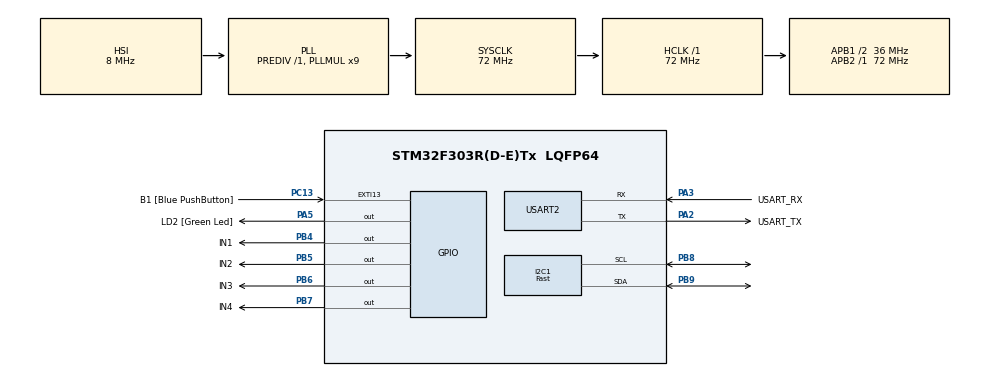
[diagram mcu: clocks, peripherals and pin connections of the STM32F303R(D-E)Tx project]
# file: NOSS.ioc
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I2C1.I2C_Speed_Mode=I2C_Fast
I2C1.Timing=0x0000020B
Mcu.Family=STM32F3
Mcu.Name=STM32F303R(D-E)Tx
Mcu.Package=LQFP64
NVIC.PriorityGroup=NVIC_PRIORITYGROUP_0
PA13.GPIO_Label=TMS
PA13.Mode=Serial_Wire
PA13.Signal=SYS_JTMS-SWDIO
PA14.GPIO_Label=TCK
PA14.Mode=Serial_Wire
PA14.Signal=SYS_JTCK-SWCLK
PA2.GPIO_Label=USART_TX
PA2.GPIO_Mode=GPIO_MODE_AF_PP
PA2.GPIO_PuPd=GPIO_NOPULL
PA2.GPIO_Speed=GPIO_SPEED_FREQ_LOW
PA2.Mode=Asynchronous
PA2.Signal=USART2_TX
PA3.GPIO_Label=USART_RX
PA3.GPIO_Mode=GPIO_MODE_AF_PP
PA3.GPIO_PuPd=GPIO_NOPULL
PA3.GPIO_Speed=GPIO_SPEED_FREQ_LOW
PA3.Mode=Asynchronous
PA3.Signal=USART2_RX
PA5.GPIO_Label=LD2 [Green Led]
PA5.GPIO_Mode=GPIO_MODE_OUTPUT_PP
PA5.GPIO_PuPd=GPIO_NOPULL
PA5.GPIO_Speed=GPIO_SPEED_FREQ_LOW
PA5.Signal=GPIO_Output
PB3.GPIO_Label=SWO
PB3.Signal=SYS_JTDO-TRACESWO
PB4.GPIO_Label=IN1
PB4.Signal=GPIO_Output
PB5.GPIO_Label=IN2
PB5.Signal=GPIO_Output
PB6.GPIO_Label=IN3
PB6.Signal=GPIO_Output
PB7.GPIO_Label=IN4
PB7.Signal=GPIO_Output
PB8.Mode=I2C
PB8.Signal=I2C1_SCL
PB9.Mode=I2C
PB9.Signal=I2C1_SDA
PC13.GPIO_Label=B1 [Blue PushButton]
PC13.GPIO_ModeDefaultEXTI=GPIO_MODE_IT_FALLING
PC13.Signal=GPXTI13
PC14-OSC32_IN.Mode=LSE-External-Oscillator
PC14-OSC32_IN.Signal=RCC_OSC32_IN
PC15-OSC32_OUT.Mode=LSE-External-Oscillator
PC15-OSC32_OUT.Signal=RCC_OSC32_OUT
PF0-OSC_IN.Mode=HSE-External-Clock-Source
PF0-OSC_IN.Signal=RCC_OSC_IN
PF1-OSC_OUT.Signal=RCC_OSC_OUT
ProjectManager.HeapSize=0x200
ProjectManager.StackSize=0x400
ProjectManager.TargetToolchain=SW4STM32
RCC.AHBFreq_Value=72000000
RCC.APB1CLKDivider=RCC_HCLK_DIV2
RCC.APB1Freq_Value=36000000
RCC.APB1TimFreq_Value=72000000
RCC.APB2Freq_Value=72000000
RCC.APB2TimFreq_Value=72000000
RCC.CortexFreq_Value=72000000
RCC.HCLKFreq_Value=72000000
RCC.HSE_VALUE=8000000
RCC.HSI_VALUE=8000000
RCC.PLLM=8
RCC.PLLMUL=RCC_PLL_MUL9
RCC.PLLN=336
RCC.PLLP=RCC_PLLP_DIV4
RCC.PLLQ=7
RCC.RCC_PLLsource_Clock_Source_FROM_HSE=RCC_HSE_PREDIV_DIV2
RCC.SYSCLKFreq_VALUE=72000000
RCC.SYSCLKSourceVirtual=RCC_SYSCLKSOURCE_PLLCLK
RCC.USBFreq_Value=72000000
TIM1.Period=0xFFFF-1
TIM1.Prescaler=72-1
USART2.VirtualMode-Asynchronous=VM_ASYNC
VP_TIM1_VS_ClockSourceINT.Mode=Internal
board=NUCLEO-F303RE

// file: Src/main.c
/* USER CODE BEGIN Header */
/**
  ******************************************************************************
  * @file           : main.c
  * @brief          : Main program body
  ******************************************************************************
  * @attention
  *
  * <h2><center>&copy; Copyright (c) 2020 STMicroelectronics.
  * All rights reserved.</center></h2>
  *
  * This software component is licensed by ST under BSD 3-Clause license,
  * the "License"; You may not use this file except in compliance with the
  * License. You may obtain a copy of the License at:
  *                        opensource.org/licenses/BSD-3-Clause
  *
  ******************************************************************************
  */
/* USER CODE END Header */

#include "mpu6050.h"
#include "main.h"
#include "tim.h"
#include "usart.h"
#include "gpio.h"
#include "stepper.h"
#include <stdio.h>

/* USER CODE BEGIN PV */
MPU6050_t MPU6050;
/* USER CODE END PV */

void SystemClock_Config(void);

/* USER CODE BEGIN 0 */
char str[100];
/* USER CODE END 0 */
//#define SERVO_180 8200
//#define SERVO_0 1800
//
//#define TURNIGY_TG9E
//
////
////	Defines
////
//
//// For Turnigy TG9e
//#ifdef    TURNIGY_TG9E
//#define SERVO_MIN 1000
//#define SERVO_MAX 2000
//#define ANGLE_MIN 0
//#define ANGLE_MAX 180
//#endif
//
//typedef struct {
//    TIM_HandleTypeDef *htim;
//    uint32_t channel;
//} servo_t;
//
//// Функция устанавливает позицию вала (в градусах)
//void set_pos(uint8_t pos) {
//    uint32_t tmp = (SERVO_180 - SERVO_0) / 180;
//    TIM2->CCR1 = SERVO_0 + tmp * pos;
//}
//
//void Servo_Init(servo_t *servo, TIM_HandleTypeDef *_htim, uint32_t _channel) {
//    servo->htim = _htim;
//    servo->channel = _channel;
//
//    HAL_TIM_PWM_Start(servo->htim, servo->channel);
//}

//
//	map help function
//
//long map(long x, long in_min, long in_max, long out_min, long out_max)
//{
//    return (x - in_min) * (out_max - out_min) / (in_max - in_min) + out_min;
//}
//int map(int st1, int fn1, int st2, int fn2, int value) {
//    return (1.0 * (value - st1)) / ((fn1 - st1) * 1.0) * (fn2 - st2) + st2;
//}
//
//void servo_write(int angle) {
//    htim2.Instance->CCR1 = map(0, 180, 50, 250, angle);
//}
//
////
////	Servo set angle function
////
//void Servo_SetAngle(servo_t *servo, uint16_t angle) {
//    if (angle < 0) angle = 0;
//    if (angle > 180) angle = 180;
//
//    uint16_t tmp = map(angle, ANGLE_MIN, ANGLE_MAX, SERVO_MIN, SERVO_MAX);
//    __HAL_TIM_SET_COMPARE(servo->htim, servo->channel, tmp);
//}
//
////
////	Servo set angle fine function
////
//void Servo_SetAngleFine(servo_t *servo, float angle) {
//    if (angle < 0) angle = 0;
//    if (angle > 180) angle = 180;
//
//    uint16_t tmp = map(angle, ANGLE_MIN, ANGLE_MAX, SERVO_MIN, SERVO_MAX);
//    __HAL_TIM_SET_COMPARE(servo->htim, servo->channel, tmp);
//}

uint16_t angle;
//servo_t servo1, servo2;
stepper_t stepper;

void delay(uint16_t us) {
    __HAL_TIM_SET_COUNTER(&htim1, 0);
    while (__HAL_TIM_GET_COUNTER(&htim1) < us);
}

void stepper_set_rpm(int rpm)  // Set rpm--> max 13, min 1,,,  went to 14 rev/min
{
    delay(60000000 / 4096 / rpm);
}

void stepper_half_drive(int step) {
    switch (step) {
        case 0:
            HAL_GPIO_WritePin(GPIOB, IN1_Pin, GPIO_PIN_SET);   // IN1
            HAL_GPIO_WritePin(GPIOB, IN2_Pin, GPIO_PIN_RESET);   // IN2
            HAL_GPIO_WritePin(GPIOB, IN3_Pin, GPIO_PIN_RESET);   // IN3
            HAL_GPIO_WritePin(GPIOB, IN4_Pin, GPIO_PIN_RESET);   // IN4
            break;

        case 1:
            HAL_GPIO_WritePin(GPIOB, IN1_Pin, GPIO_PIN_SET);   // IN1
            HAL_GPIO_WritePin(GPIOB, IN2_Pin, GPIO_PIN_SET);   // IN2
            HAL_GPIO_WritePin(GPIOB, IN3_Pin, GPIO_PIN_RESET);   // IN3
            HAL_GPIO_WritePin(GPIOB, IN4_Pin, GPIO_PIN_RESET);   // IN4
            break;

        case 2:
            HAL_GPIO_WritePin(GPIOB, IN1_Pin, GPIO_PIN_RESET);   // IN1
            HAL_GPIO_WritePin(GPIOB, IN2_Pin, GPIO_PIN_SET);   // IN2
            HAL_GPIO_WritePin(GPIOB, IN3_Pin, GPIO_PIN_RESET);   // IN3
            HAL_GPIO_WritePin(GPIOB, IN4_Pin, GPIO_PIN_RESET);   // IN4
            break;

        case 3:
            HAL_GPIO_WritePin(GPIOB, IN1_Pin, GPIO_PIN_RESET);   // IN1
            HAL_GPIO_WritePin(GPIOB, IN2_Pin, GPIO_PIN_SET);   // IN2
            HAL_GPIO_WritePin(GPIOB, IN3_Pin, GPIO_PIN_SET);   // IN3
            HAL_GPIO_WritePin(GPIOB, IN4_Pin, GPIO_PIN_RESET);   // IN4
            break;

        case 4:
            HAL_GPIO_WritePin(GPIOB, IN1_Pin, GPIO_PIN_RESET);   // IN1
            HAL_GPIO_WritePin(GPIOB, IN2_Pin, GPIO_PIN_RESET);   // IN2
            HAL_GPIO_WritePin(GPIOB, IN3_Pin, GPIO_PIN_SET);   // IN3
            HAL_GPIO_WritePin(GPIOB, IN4_Pin, GPIO_PIN_RESET);   // IN4
            break;

        case 5:
            HAL_GPIO_WritePin(GPIOB, IN1_Pin, GPIO_PIN_RESET);   // IN1
            HAL_GPIO_WritePin(GPIOB, IN2_Pin, GPIO_PIN_RESET);   // IN2
            HAL_GPIO_WritePin(GPIOB, IN3_Pin, GPIO_PIN_SET);   // IN3
            HAL_GPIO_WritePin(GPIOB, IN4_Pin, GPIO_PIN_SET);   // IN4
            break;

        case 6:
            HAL_GPIO_WritePin(GPIOB, IN1_Pin, GPIO_PIN_RESET);   // IN1
            HAL_GPIO_WritePin(GPIOB, IN2_Pin, GPIO_PIN_RESET);   // IN2
            HAL_GPIO_WritePin(GPIOB, IN3_Pin, GPIO_PIN_RESET);   // IN3
            HAL_GPIO_WritePin(GPIOB, IN4_Pin, GPIO_PIN_SET);   // IN4
            break;

        case 7:
            HAL_GPIO_WritePin(GPIOB, IN1_Pin, GPIO_PIN_SET);   // IN1
            HAL_GPIO_WritePin(GPIOB, IN2_Pin, GPIO_PIN_RESET);   // IN2
            HAL_GPIO_WritePin(GPIOB, IN3_Pin, GPIO_PIN_RESET);   // IN3
            HAL_GPIO_WritePin(GPIOB, IN4_Pin, GPIO_PIN_SET);   // IN4
            break;

    }
}

void stepper_step_angle(float angle, int direction, int rpm) {
    float anglepersequence = 0.703125;  // 360 = 512 sequences
    int numberofsequences = (int) (angle / anglepersequence);

    for (int seq = 0; seq < numberofsequences; seq++) {
        if (direction == 0)  // for clockwise
        {
            for (int step = 7; step >= 0; step--) {
                stepper_half_drive(step);
                stepper_set_rpm(rpm);
            }

        } else if (direction == 1)  // for anti-clockwise
        {
            for (int step = 0; step < 8; step++) {
                stepper_half_drive(step);
                stepper_set_rpm(rpm);
            }
        }
    }
}

int setpoint = 0;   // заданная величина, которую должен поддерживать регулятор
int input = 0;      // сигнал с датчика (например температура, которую мы регулируем)
int output = 0;     // выход с регулятора на управляющее устройство (например величина ШИМ или угол поворота серво)
int pidMin = -255;     // минимальный выход с регулятора
int pidMax = 255;   // максимальный выход с регулятора
// коэффициенты
float Kp = 1.0;
float Ki = 1.0;
float Kd = 0/5;
float _dt_s = 0.1; // время итерации в секундах
// вспомогательные переменные
int prevInput = 0;
float integral = 0.0;

#define constrain(amt, low, high) ((amt)<(low)?(low):((amt)>(high)?(high):(amt)))

int computePID() {
    float error = setpoint - input;           // ошибка регулирования
    float delta_input = prevInput - input;    // изменение входного сигнала
    prevInput = input;
    output = 0;
    output += (float) error * Kp;                  // пропорционально ошибке регулирования
    output += (float) delta_input * Kd / _dt_s;    // дифференциальная составляющая
    integral += (float) error * Ki * _dt_s;        // расчёт интегральной составляющей
    // тут можно ограничить интегральную составляющую!
    output += integral;                           // прибавляем интегральную составляющую
    output = constrain(output, pidMin, pidMax);   // ограничиваем выход
    return output;
}

int main(void) {

    /* MCU Configuration--------------------------------------------------------*/

    /* Reset of all peripherals, Initializes the Flash interface and the Systick. */
    HAL_Init();

    /* Configure the system clock */
    SystemClock_Config();

    /* Initialize all configured peripherals */
    MX_GPIO_Init();
    MX_I2C1_Init();
    MX_USART2_UART_Init();
    MX_TIM1_Init();
    HAL_TIM_Base_Start(&htim1);
    //MX_TIM2_Init();
    //Servo_Init(&servo1, &htim2, TIM_CHANNEL_1);

    /* USER CODE BEGIN 2 */
    while (MPU6050_Init(&hi2c1) == 1);
    /* USER CODE END 2 */
    //uint8_t i;
    /* Infinite loop */
    /* USER CODE BEGIN WHILE */
    //uint32_t t = HAL_GetTick();

//    stepper_init(&stepper, 200, in1, in2, in3, in4);
//    setSpeed(&stepper, 60);
//    step(&stepper, 100);

    while (1) {

        //uint32_t t = HAL_GetTick();
//        step(&stepper, 100);
//        HAL_Delay(1000);
//        step(&stepper, -100);
//        HAL_Delay(1000);
        /* USER CODE END WHILE */
        MPU6050_Read_All(&hi2c1, &MPU6050);
        HAL_Delay(10);
//
        double y = MPU6050.KalmanAngleY;
//        double x = MPU6050.KalmanAngleX;
        input = (int)y;

        int out = computePID();

        if (out > 0) {
            stepper_step_angle((float)out, 1, 13);
        } else {
            uint out1 = out * -1;
            stepper_step_angle((float)out1, 0, 13);
        }

//        int32_t tmp1 = (int32_t)y;
//        double tmp_frac = y - tmp1;
//        int32_t tmp2 = trunc(tmp_frac * 1000);

        //sprintf(str, "Y: %d.%04d \r\n", tmp1, tmp2);
//        HAL_UART_Transmit(&huart2, y, sizeof(str), 100);

        char msg[31];
        uint16_t len = sprintf(msg, "y: %d out: %d \r\n", (int16_t) input, (int16_t) out);
        HAL_UART_Transmit(&huart2, (uint8_t *) msg, len, HAL_MAX_DELAY);
//        for (i=0;i<=180;i++) {
//            HAL_Delay(1000);
//            set_pos(i);
//        }
//        for(i = 0; i <= 180; i++)
//        {
//            servo_write(i);
//            HAL_Delay(10);
//        }
//        for(i = 180; i >= 0; i--)
//        {
//            servo_write(i);
//            HAL_Delay(10);
//        }
        //Servo_SetAngle(&servo1, 0);
        //Servo_SetAngle(&servo2, 90);
        //HAL_Delay(1000);

//        Servo_SetAngle(&servo1, 90);
//        Servo_SetAngle(&servo2, 180);
//        HAL_Delay(1000);
        //HAL_Delay(100);
    }
}

void SystemClock_Config(void) {
    RCC_OscInitTypeDef RCC_OscInitStruct = {0};
    RCC_ClkInitTypeDef RCC_ClkInitStruct = {0};
    RCC_PeriphCLKInitTypeDef PeriphClkInit = {0};

    /** Initializes the CPU, AHB and APB busses clocks
    */
    RCC_OscInitStruct.OscillatorType = RCC_OSCILLATORTYPE_HSI;
    RCC_OscInitStruct.HSIState = RCC_HSI_ON;
    RCC_OscInitStruct.HSICalibrationValue = RCC_HSICALIBRATION_DEFAULT;
    RCC_OscInitStruct.PLL.PLLState = RCC_PLL_ON;
    RCC_OscInitStruct.PLL.PLLSource = RCC_PLLSOURCE_HSI;
    RCC_OscInitStruct.PLL.PLLMUL = RCC_PLL_MUL9;
    RCC_OscInitStruct.PLL.PREDIV = RCC_PREDIV_DIV1;
    if (HAL_RCC_OscConfig(&RCC_OscInitStruct) != HAL_OK) {
        Error_Handler();
    }
    /** Initializes the CPU, AHB and APB busses clocks
    */
    RCC_ClkInitStruct.ClockType = RCC_CLOCKTYPE_HCLK | RCC_CLOCKTYPE_SYSCLK
                                  | RCC_CLOCKTYPE_PCLK1 | RCC_CLOCKTYPE_PCLK2;
    RCC_ClkInitStruct.SYSCLKSource = RCC_SYSCLKSOURCE_PLLCLK;
    RCC_ClkInitStruct.AHBCLKDivider = RCC_SYSCLK_DIV1;
    RCC_ClkInitStruct.APB1CLKDivider = RCC_HCLK_DIV2;
    RCC_ClkInitStruct.APB2CLKDivider = RCC_HCLK_DIV1;

    if (HAL_RCC_ClockConfig(&RCC_ClkInitStruct, FLASH_LATENCY_2) != HAL_OK) {
        Error_Handler();
    }
    PeriphClkInit.PeriphClockSelection = RCC_PERIPHCLK_USART2 | RCC_PERIPHCLK_I2C1
                                         | RCC_PERIPHCLK_TIM1;
    PeriphClkInit.Usart2ClockSelection = RCC_USART2CLKSOURCE_PCLK1;
    PeriphClkInit.I2c1ClockSelection = RCC_I2C1CLKSOURCE_HSI;
    PeriphClkInit.Tim1ClockSelection = RCC_TIM1CLK_HCLK;
    if (HAL_RCCEx_PeriphCLKConfig(&PeriphClkInit) != HAL_OK) {
        Error_Handler();
    }
}

void Error_Handler(void) {
    /* USER CODE BEGIN Error_Handler_Debug */
    /* User can add his own implementation to report the HAL error return state */
    HAL_GPIO_WritePin(LD2_GPIO_Port, LD2_Pin, GPIO_PIN_RESET);
    /* USER CODE END Error_Handler_Debug */
}

/************************ (C) COPYRIGHT STMicroelectronics *****END OF FILE****/
